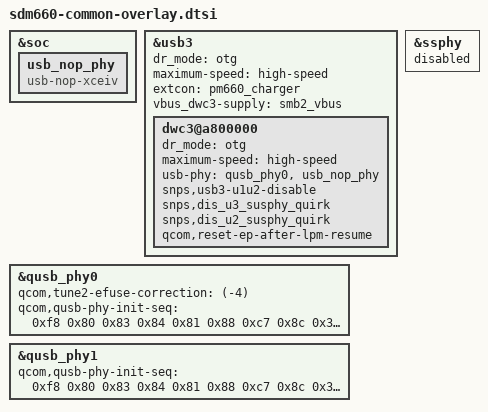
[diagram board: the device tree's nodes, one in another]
/* Copyright (c) 2016-2017, The Linux Foundation. All rights reserved.
 *
 * This program is free software; you can redistribute it and/or modify
 * it under the terms of the GNU General Public License version 2 and
 * only version 2 as published by the Free Software Foundation.
 *
 * This program is distributed in the hope that it will be useful,
 * but WITHOUT ANY WARRANTY; without even the implied warranty of
 * MERCHANTABILITY or FITNESS FOR A PARTICULAR PURPOSE.  See the
 * GNU General Public License for more details.
 */

&soc {
	usb_nop_phy: usb_nop_phy {
		compatible = "usb-nop-xceiv";
	};
};

&usb3 {
	status = "okay";
	dr_mode = "otg";
	maximum-speed = "high-speed";
	extcon = <&pm660_charger>;
	vbus_dwc3-supply = <&smb2_vbus>;

	dwc3@a800000 {
		status = "okay";
		dr_mode = "otg";
		maximum-speed = "high-speed";
		usb-phy = <&qusb_phy0>, <&usb_nop_phy>;

		snps,usb3-u1u2-disable;
		snps,dis_u3_susphy_quirk;
		snps,dis_u2_susphy_quirk;
		qcom,reset-ep-after-lpm-resume;
	};
};

&qusb_phy0 {
	status = "okay";
	qcom,tune2-efuse-correction = <(-4)>;
	qcom,qusb-phy-init-seq = <0xf8 0x80
				  0x83 0x84
				  0x81 0x88
				  0xc7 0x8c
				  0x30 0x08
				  0x79 0x0c
				  0x21 0x10
				  0x14 0x9c
				  0x9f 0x1c
				  0x00 0x18>;
};

&ssphy {
	status = "disabled";
};

&qusb_phy1 {
	qcom,qusb-phy-init-seq = <0xf8 0x80
				  0x83 0x84
				  0x81 0x88
				  0xc7 0x8c
				  0x30 0x08
				  0x79 0x0c
				  0x21 0x10
				  0x14 0x9c
				  0x9f 0x1c
				  0x00 0x18>;
};
